# TMS320F280049 register map
Vendor: Texas Instruments; Series: C2000 F28004x; File version: 0.2.0-generated
Registers are 16-bit, read-write, reset 0x0 unless marked. A register's access mark holds for its fields unless they carry their own. Offsets are from the block's base; [hi:lo] are bit positions; {n}, {i} and the like mark numbered series.

## DCSMBANK0Z1REGS — DCSM BANK0 Z1 Registers
Base 0x000BE000
0x00 B0_Z1_LINKPOINTER 32-bit — Zone 1 Link Pointer for flash BANK0
  [31:28] LINKPOINTER — Zone1 LINK Pointer for zone Flash BANK0
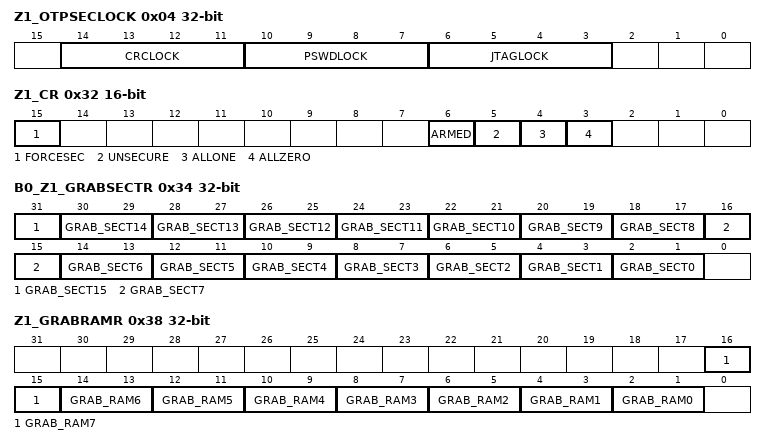
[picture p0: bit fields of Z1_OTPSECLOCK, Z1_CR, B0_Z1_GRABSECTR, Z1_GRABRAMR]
0x04 Z1_OTPSECLOCK 32-bit — Zone 1 OTP Secure JTAG lock
  [14:11] CRCLOCK — Zone1 CRC Lock.
  [10:7] PSWDLOCK — Zone1 Password Lock.
  [6:3] JTAGLOCK — Zone1 JTAG Lock.
0x08 Z1_BOOTDEF_HIGH 32-bit — Boot definition (high 32bit)
  [31] BOOTDEF_HIGH — Boot definition (high) register
0x0C B0_Z1_LINKPOINTERERR 32-bit — Link Pointer Error for flash BANK0
  [31:28] Z1_LINKPOINTERERR — Error to Resolve Z1 Link pointer from OTP loaded values
0x10 Z1_BOOTPIN_CONFIG 32-bit — Boot Pin Configuration
  [31] BOOTPIN_CONIFG — BOOT Pin configuration
0x14 Z1_GPREG2 32-bit — Zone1 General Purpose Register-2
  [31] GPREG2 — General Purpose Register-2
0x18 Z1_BOOTDEF_LOW 32-bit — Boot definition (low 32bit)
  [31] BOOTDEF_LOW — Boot definition (low) register
0x20 Z1_CSMKEY0 32-bit — Zone 1 CSM Key 0
  [31] Z1_CSMKEY0 — Word0 to unlock Zone1, should match Z1_CSMPSWD0.
{0x20+4i} Z1_CSMKEY{i} 32-bit (i=1..3) — Zone 1 CSM Key {i}
  [31] Z1_CSMKEY{i} — Word{i} to unlock Zone1, should match Z1_CSMPSWD{i}
0x32 Z1_CR — Zone 1 CSM Control Register
  [15] FORCESEC — Force Secure
  [6] ARMED — CSM Passwords Read Status
  [5] UNSECURE — CSMPSWD Match CSMKEY
  [4] ALLONE — CSMPSWD All Ones
  [3] ALLZERO — CSMPSWD All Zeros
0x34 B0_Z1_GRABSECTR 32-bit — Zone 1 Grab Flash BANK0 Sectors Register
  [31] GRAB_SECT15 — Grab Flash Sector 15 in BANK0
  [2n+2:2n+1] GRAB_SECT{n} (n=0..14) — Grab Flash Sector {n} in BANK0
0x38 Z1_GRABRAMR 32-bit — Zone 1 Grab RAM Blocks Register
  [2n+2:2n+1] GRAB_RAM{n} (n=0..7) — Grab RAM LS{n}
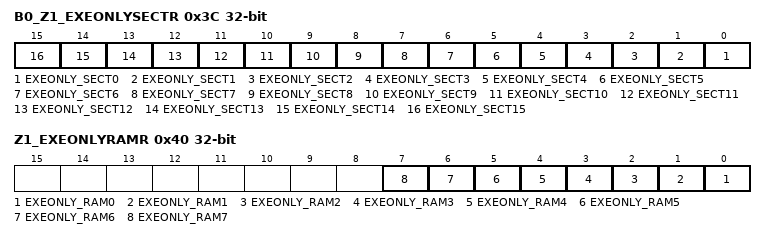
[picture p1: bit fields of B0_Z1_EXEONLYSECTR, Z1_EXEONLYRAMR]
0x3C B0_Z1_EXEONLYSECTR 32-bit — Zone 1 Flash BANK0 Execute_Only Sector Register
  [n] EXEONLY_SECT{n} (n=0..15) — Execute-Only Flash Sector {n} in Flash BANK0
0x40 Z1_EXEONLYRAMR 32-bit — Zone 1 RAM Execute_Only Block Register
  [n] EXEONLY_RAM{n} (n=0..7) — Execute-Only RAM LS{n}

## DCSMBANK0Z2REGS — DCSM BANK0 Z2 Registers
Base 0x000BE080
0x00 B0_Z2_LINKPOINTER 32-bit — Zone 2 Link Pointer for flash BANK0
  [31:28] LINKPOINTER — Zone2 LINK Pointer in Flash BANK0
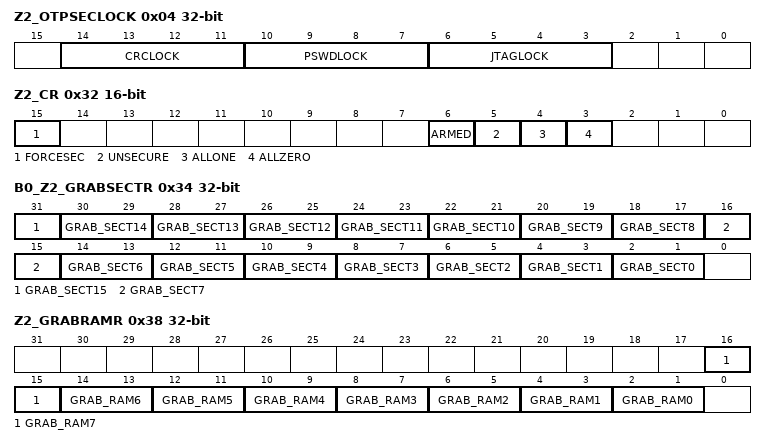
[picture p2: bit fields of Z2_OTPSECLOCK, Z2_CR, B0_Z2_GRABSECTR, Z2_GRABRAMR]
0x04 Z2_OTPSECLOCK 32-bit — Zone 2 OTP Secure JTAG lock
  [14:11] CRCLOCK — Zone2 CRC Lock.
  [10:7] PSWDLOCK — Zone2 Password Lock.
  [6:3] JTAGLOCK — Zone2 JTAG Lock.
0x0C B0_Z2_LINKPOINTERERR 32-bit — Link Pointer Error for flash BANK0
  [31:28] Z2_LINKPOINTERERR — Error to Resolve Z2 Link pointer from OTP loaded values
0x20 Z2_CSMKEY0 32-bit — Zone 2 CSM Key 0
  [31] Z2_CSMKEY0 — Word0 to unlock Zone2, should match Z2_CSMPSWD0.
{0x20+4i} Z2_CSMKEY{i} 32-bit (i=1..3) — Zone 2 CSM Key {i}
  [31] Z2_CSMKEY{i} — Word{i} to unlock Zone2, should match Z2_CSMPSWD{i}
0x32 Z2_CR — Zone 2 CSM Control Register
  [15] FORCESEC — Force Secure
  [6] ARMED — CSM Passwords Read Status
  [5] UNSECURE — CSMPSWD Match CSMKEY
  [4] ALLONE — CSMPSWD All Ones
  [3] ALLZERO — CSMPSWD All Zeros
0x34 B0_Z2_GRABSECTR 32-bit — Zone 2 Grab Flash BANK0 Sectors Register
  [31] GRAB_SECT15 — Grab Flash Sector 15 in Flash BANK0
  [2n+2:2n+1] GRAB_SECT{n} (n=0..14) — Grab Flash Sector {n} in Flash BANK0
0x38 Z2_GRABRAMR 32-bit — Zone 2 Grab RAM Blocks Register
  [2n+2:2n+1] GRAB_RAM{n} (n=0..7) — Grab RAM LS{n}
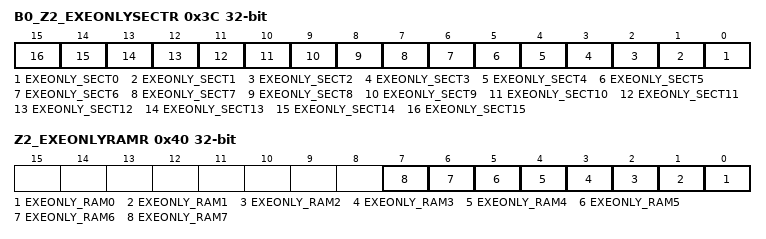
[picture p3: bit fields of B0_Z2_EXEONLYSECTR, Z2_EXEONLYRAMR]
0x3C B0_Z2_EXEONLYSECTR 32-bit — Zone 2 Flash BANK0 Execute_Only Sector Register
  [n] EXEONLY_SECT{n} (n=0..15) — Execute-Only Flash Sector {n} in Flash BANK0
0x40 Z2_EXEONLYRAMR 32-bit — Zone 2 RAM Execute_Only Block Register
  [n] EXEONLY_RAM{n} (n=0..7) — Execute-Only RAM LS{n}

## DCSMCOMMONREGS — DCSM COMMON Registers
Base 0x000BE0E0
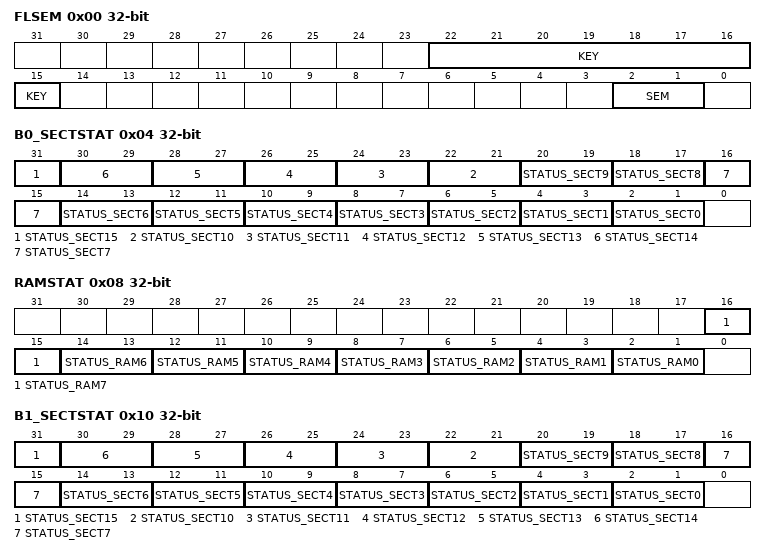
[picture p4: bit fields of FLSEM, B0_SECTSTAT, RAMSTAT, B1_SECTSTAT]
0x00 FLSEM 32-bit — Flash Wrapper Semaphore Register
  [22:15] KEY — Semaphore Key
  [2:1] SEM — Flash Semaphore Bit
0x04 B0_SECTSTAT 32-bit — Flash BANK0 Sectors Status Register
  [31] STATUS_SECT15 — Zone Status Flash BANK0 Sector 15
  [2n+2:2n+1] STATUS_SECT{n} (n=9..14) — Zone Status Flash BANK0 Sector {n}
  [18:17] STATUS_SECT8 — Zone Status Flash BANK0 sector 8
  [2n+2:2n+1] STATUS_SECT{n} (n=2..7) — Zone Status Flash BANK0 Sector {n}
  [4:3] STATUS_SECT1 — Zone Status Flash BANK0 sector 1
  [2:1] STATUS_SECT0 — Zone Status Flash BANK0 Sector 0
0x08 RAMSTAT 32-bit — RAM Status Register
  [2n+2:2n+1] STATUS_RAM{n} (n=0..7) — Zone Status RAM LS{n}
0x10 B1_SECTSTAT 32-bit — Flash BANK1 Sectors Status Register
  [31] STATUS_SECT15 — Zone Status Flash BANK1 Sector 15
  [2n+2:2n+1] STATUS_SECT{n} (n=9..14) — Zone Status Flash BANK1 Sector {n}
  [18:17] STATUS_SECT8 — Zone Status Flash BANK1 sector 8
  [2n+2:2n+1] STATUS_SECT{n} (n=2..7) — Zone Status Flash BANK1 Sector {n}
  [4:3] STATUS_SECT1 — Zone Status Flash BANK1 sector 1
  [2:1] STATUS_SECT0 — Zone Status Flash BANK1 Sector 0
0x14 SECERRSTAT 32-bit — Security Error Status Register
  [0] ERR — Security Configuration load Error Status
0x18 SECERRCLR 32-bit — Security Error Clear Register
  [0] ERR — Clear Security Configuration Load Error Status Bit
0x1C SECERRFRC 32-bit — Security Error Force Register
  [0] ERR — Set Security Configuration Load Error Status Bit
